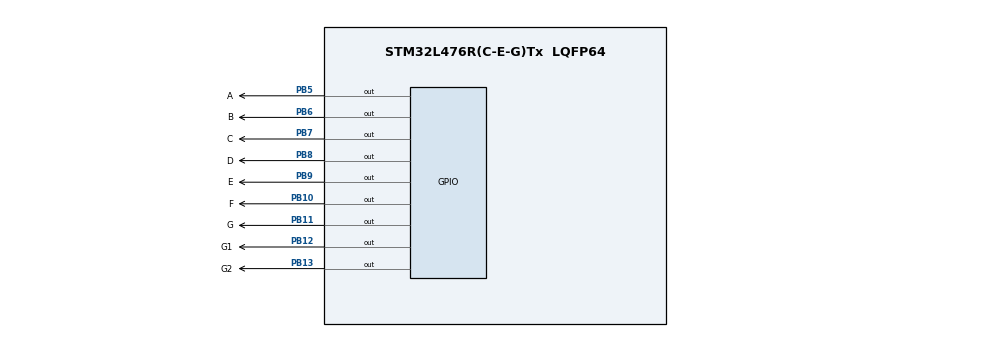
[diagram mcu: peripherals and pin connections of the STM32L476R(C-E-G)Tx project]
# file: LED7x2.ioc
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Mcu.Family=STM32L4
Mcu.Name=STM32L476R(C-E-G)Tx
Mcu.Package=LQFP64
NVIC.PriorityGroup=NVIC_PRIORITYGROUP_4
NVIC.RCC_IRQn=true\:0\:0\:false\:false\:true\:true\:false
PB10.GPIO_Label=F
PB10.GPIO_Speed=GPIO_SPEED_FREQ_MEDIUM
PB10.Signal=GPIO_Output
PB11.GPIO_Label=G
PB11.GPIO_Speed=GPIO_SPEED_FREQ_MEDIUM
PB11.Signal=GPIO_Output
PB12.GPIO_Label=G1
PB12.GPIO_ModeDefaultOutputPP=GPIO_MODE_OUTPUT_OD
PB12.GPIO_PuPd=GPIO_NOPULL
PB12.GPIO_Speed=GPIO_SPEED_FREQ_MEDIUM
PB12.Signal=GPIO_Output
PB13.GPIO_Label=G2
PB13.GPIO_ModeDefaultOutputPP=GPIO_MODE_OUTPUT_OD
PB13.GPIO_PuPd=GPIO_NOPULL
PB13.GPIO_Speed=GPIO_SPEED_FREQ_MEDIUM
PB13.Signal=GPIO_Output
PB5.GPIO_Label=A
PB5.GPIO_Speed=GPIO_SPEED_FREQ_MEDIUM
PB5.Signal=GPIO_Output
PB6.GPIO_Label=B
PB6.GPIO_Speed=GPIO_SPEED_FREQ_MEDIUM
PB6.Signal=GPIO_Output
PB7.GPIO_Label=C
PB7.GPIO_Speed=GPIO_SPEED_FREQ_MEDIUM
PB7.Signal=GPIO_Output
PB8.GPIO_Label=D
PB8.GPIO_Speed=GPIO_SPEED_FREQ_MEDIUM
PB8.Signal=GPIO_Output
PB9.GPIO_Label=E
PB9.GPIO_Speed=GPIO_SPEED_FREQ_MEDIUM
PB9.Signal=GPIO_Output
PC14-OSC32_IN\ (PC14).Mode=LSE-External-Oscillator
PC14-OSC32_IN\ (PC14).Signal=RCC_OSC32_IN
PC15-OSC32_OUT\ (PC15).Mode=LSE-External-Oscillator
PC15-OSC32_OUT\ (PC15).Signal=RCC_OSC32_OUT
ProjectManager.HeapSize=0x200
ProjectManager.StackSize=0x400
ProjectManager.TargetToolchain=STM32CubeIDE
RCC.HSE_VALUE=8000000
RCC.HSI_VALUE=16000000
RCC.LSCOSource1=RCC_LSCOSOURCE_LSE
RCC.MSI_VALUE=4000000
RCC.RCC_MCO1Source=RCC_MCO1SOURCE_LSE
RCC.RTCClockSelection=RCC_RTCCLKSOURCE_LSE
RCC.VCOOutputFreq_Value=32000000
VP_RTC_VS_RTC_Activate.Mode=RTC_Enabled
VP_SYS_V_PVD_IN.Mode=Mode_PVD_Int
board=custom

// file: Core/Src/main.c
/* USER CODE BEGIN Header */
/**
  ******************************************************************************
  * @file           : main.c
  * @brief          : Main program body
  ******************************************************************************
  * @attention
  *
  * <h2><center>&copy; Copyright (c) 2021 STMicroelectronics.
  * All rights reserved.</center></h2>
  *
  * This software component is licensed by ST under BSD 3-Clause license,
  * the "License"; You may not use this file except in compliance with the
  * License. You may obtain a copy of the License at:
  *                        opensource.org/licenses/BSD-3-Clause
  *
  ******************************************************************************
  */
/* USER CODE END Header */
#include "main.h"
#include "rtc.h"
#include "gpio.h"

/* USER CODE BEGIN Includes */
#include "led7.h"
/* USER CODE END Includes */

void SystemClock_Config(void);

int main(void)
{

  /* MCU Configuration--------------------------------------------------------*/

  /* Reset of all peripherals, Initializes the Flash interface and the Systick. */
  HAL_Init();

  /* Configure the system clock */
  SystemClock_Config();

  /* Initialize all configured peripherals */
  MX_GPIO_Init();
  MX_RTC_Init();

  /* Infinite loop */
  /* USER CODE BEGIN WHILE */

  int8_t n = 99;
  while (n > 0)
  {
	  led_set_dec(n, 100);
	  n--;
    /* USER CODE END WHILE */

    /* USER CODE BEGIN 3 */
  }
  led_reset();
  /* USER CODE END 3 */
}

void SystemClock_Config(void)
{
  RCC_OscInitTypeDef RCC_OscInitStruct = {0};
  RCC_ClkInitTypeDef RCC_ClkInitStruct = {0};

  /** Configure the main internal regulator output voltage
  */
  if (HAL_PWREx_ControlVoltageScaling(PWR_REGULATOR_VOLTAGE_SCALE1) != HAL_OK)
  {
    Error_Handler();
  }
  /** Configure LSE Drive Capability
  */
  HAL_PWR_EnableBkUpAccess();
  __HAL_RCC_LSEDRIVE_CONFIG(RCC_LSEDRIVE_LOW);
  /** Initializes the RCC Oscillators according to the specified parameters
  * in the RCC_OscInitTypeDef structure.
  */
  RCC_OscInitStruct.OscillatorType = RCC_OSCILLATORTYPE_LSE|RCC_OSCILLATORTYPE_MSI;
  RCC_OscInitStruct.LSEState = RCC_LSE_ON;
  RCC_OscInitStruct.MSIState = RCC_MSI_ON;
  RCC_OscInitStruct.MSICalibrationValue = 0;
  RCC_OscInitStruct.MSIClockRange = RCC_MSIRANGE_6;
  RCC_OscInitStruct.PLL.PLLState = RCC_PLL_NONE;
  if (HAL_RCC_OscConfig(&RCC_OscInitStruct) != HAL_OK)
  {
    Error_Handler();
  }
  /** Initializes the CPU, AHB and APB buses clocks
  */
  RCC_ClkInitStruct.ClockType = RCC_CLOCKTYPE_HCLK|RCC_CLOCKTYPE_SYSCLK
                              |RCC_CLOCKTYPE_PCLK1|RCC_CLOCKTYPE_PCLK2;
  RCC_ClkInitStruct.SYSCLKSource = RCC_SYSCLKSOURCE_MSI;
  RCC_ClkInitStruct.AHBCLKDivider = RCC_SYSCLK_DIV1;
  RCC_ClkInitStruct.APB1CLKDivider = RCC_HCLK_DIV1;
  RCC_ClkInitStruct.APB2CLKDivider = RCC_HCLK_DIV1;

  if (HAL_RCC_ClockConfig(&RCC_ClkInitStruct, FLASH_LATENCY_0) != HAL_OK)
  {
    Error_Handler();
  }
  /** Enable MSI Auto calibration
  */
  HAL_RCCEx_EnableMSIPLLMode();
}

void Error_Handler(void)
{
  __disable_irq();
  while (1)
  {
  }
}

/************************ (C) COPYRIGHT STMicroelectronics *****END OF FILE****/
